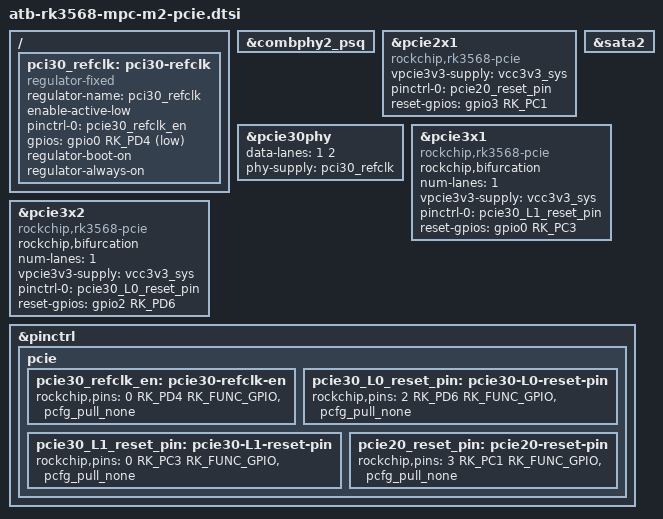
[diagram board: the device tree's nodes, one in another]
//------------------------------------------------------------------------------
// PCI 2.0 + SATA
//------------------------------------------------------------------------------

// This controller is phy for pcie2x1 and sata2 controllers
&combphy2_psq {
	// used for SATA
	status = "okay";
};

// This controller is connected to X13
&pcie2x1 {
	vpcie3v3-supply = <&vcc3v3_sys>;
	compatible = "rockchip,rk3568-pcie";

	pinctrl-names = "default";
	pinctrl-0 = <&pcie20_reset_pin>;
	reset-gpios = <&gpio3 RK_PC1 GPIO_ACTIVE_HIGH>;

	status = "okay";
};

&sata2 {
	status = "okay";
};

//------------------------------------------------------------------------------
// PCI 3.0
//------------------------------------------------------------------------------
// This controller has two lanes which can be organized:
//   * 1x PCIE3 x2
//   * 2x PCIE3 x1

// If bifurcation mode is activated:
//   * Lane 1 is controlled by pcie3x1
//   * Lane 0 is controlled by pcie3x2

//------------------------------------------------------------------------------
/{
	pci30_refclk: pci30-refclk {
		compatible = "regulator-fixed";
		regulator-name = "pci30_refclk";
		enable-active-low;

		pinctrl-names = "default";
		pinctrl-0 = <&pcie30_refclk_en>;
		gpios = <&gpio0 RK_PD4 GPIO_ACTIVE_LOW>;

		regulator-boot-on;
		regulator-always-on;
	};
};

&pcie30phy {
	data-lanes = <1 2>;
	phy-supply = <&pci30_refclk>;
	status = "okay";
};

//------------------------------------------------------------------------------
// Lane 1
&pcie3x1 {
	rockchip,bifurcation;
	num-lanes = <1>;
	vpcie3v3-supply = <&vcc3v3_sys>;
	compatible = "rockchip,rk3568-pcie";

	pinctrl-names = "default";
	pinctrl-0 = <&pcie30_L1_reset_pin>;
	reset-gpios = <&gpio0 RK_PC3 GPIO_ACTIVE_HIGH>;

	status = "okay";
};

//------------------------------------------------------------------------------
// Lane 0
&pcie3x2 {
	rockchip,bifurcation;
	num-lanes = <1>;
	vpcie3v3-supply = <&vcc3v3_sys>;
	compatible = "rockchip,rk3568-pcie";

	pinctrl-names = "default";
	pinctrl-0 = <&pcie30_L0_reset_pin>;
	reset-gpios = <&gpio2 RK_PD6 GPIO_ACTIVE_HIGH>;

	status = "okay";
};

//------------------------------------------------------------------------------
&pinctrl {
	pcie {
		pcie30_refclk_en: pcie30-refclk-en {
			rockchip,pins = <0 RK_PD4 RK_FUNC_GPIO &pcfg_pull_none>;
		};

		// Lane 0
		pcie30_L0_reset_pin: pcie30-L0-reset-pin {
			rockchip,pins = <2 RK_PD6 RK_FUNC_GPIO &pcfg_pull_none>;
		};

		// Lane 1
		pcie30_L1_reset_pin: pcie30-L1-reset-pin {
			rockchip,pins = <0 RK_PC3 RK_FUNC_GPIO &pcfg_pull_none>;
		};

		pcie20_reset_pin: pcie20-reset-pin {
			rockchip,pins = <3 RK_PC1 RK_FUNC_GPIO &pcfg_pull_none>;
		};
	};
};
